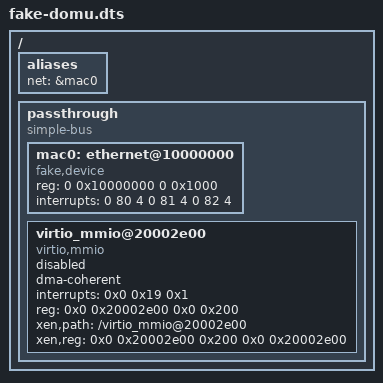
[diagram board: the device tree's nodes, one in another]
/dts-v1/;

/ {
    /* #*cells are here to keep DTC happy */
    #address-cells = <2>;
    #size-cells = <2>;

    aliases {
        net = &mac0;
    };

    passthrough {
        compatible = "simple-bus";
        ranges;
        #address-cells = <2>;
        #size-cells = <2>;
        mac0: ethernet@10000000 {
            compatible = "fake,device";
            reg = <0 0x10000000 0 0x1000>;
            interrupts = <0 80 4  0 81 4  0 82 4>;
        };

        virtio_mmio@20002e00 {
            dma-coherent;
            interrupts = <0x0 0x19 0x1>;
            reg = <0x0 0x20002e00 0x0 0x200>;
            compatible = "virtio,mmio";
            status = "nok";
            xen,path = "/virtio_mmio@20002e00";
            xen,reg = <0x0 0x20002e00 0x200 0x0 0x20002e00>;
        };
    };
};

